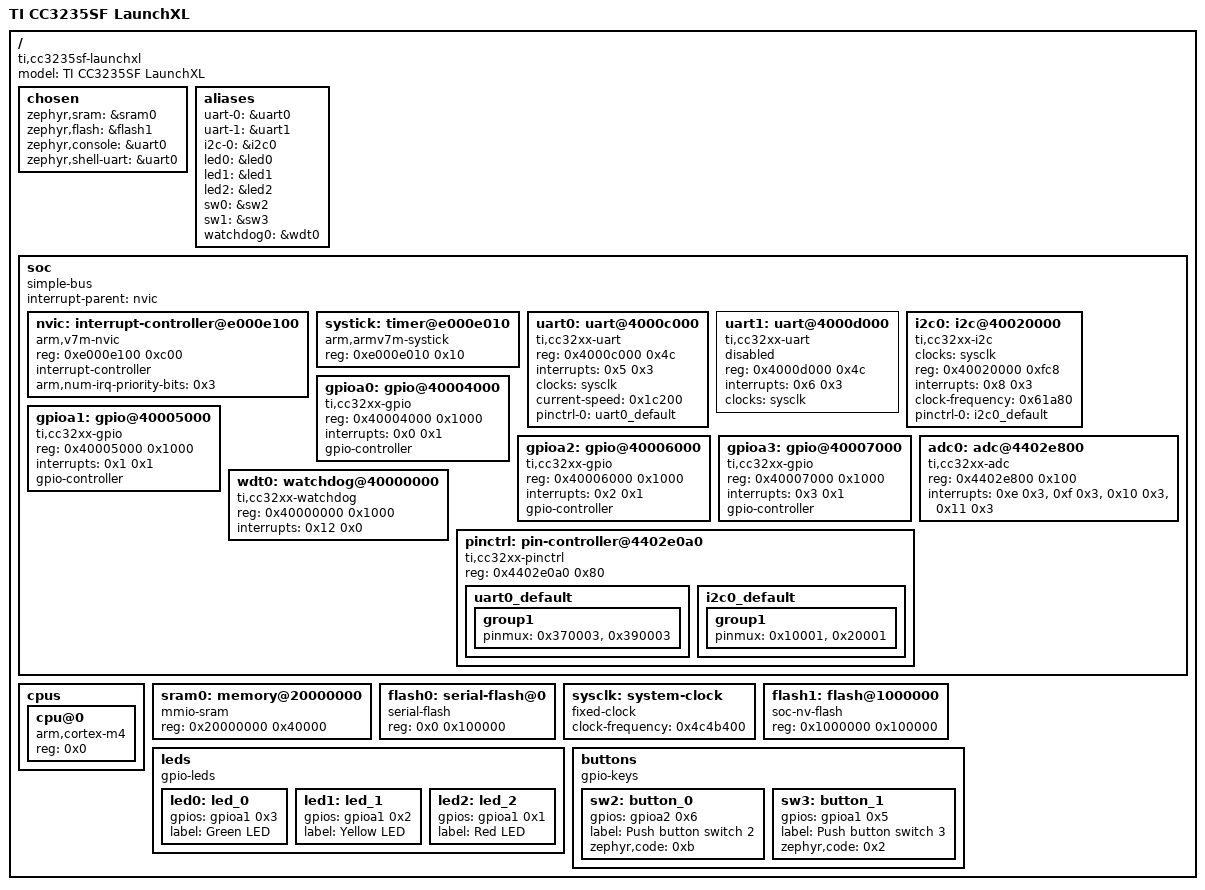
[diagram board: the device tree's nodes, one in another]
/dts-v1/;

/* node '/' defined in zephyr/dts/common/skeleton.dtsi:9 */
/ {
	#address-cells = < 0x1 >;            /* in zephyr/dts/common/skeleton.dtsi:10 */
	#size-cells = < 0x1 >;               /* in zephyr/dts/common/skeleton.dtsi:11 */
	model = "TI CC3235SF LaunchXL";      /* in zephyr/boards/ti/cc3235sf_launchxl/cc3235sf_launchxl.dts:14 */
	compatible = "ti,cc3235sf-launchxl",
	             "ti,cc3235sf",
	             "ti,cc32xx";            /* in zephyr/boards/ti/cc3235sf_launchxl/cc3235sf_launchxl.dts:15 */

	/* node '/chosen' defined in zephyr/dts/common/skeleton.dtsi:13 */
	chosen {
		zephyr,sram = &sram0;       /* in zephyr/boards/ti/cc3235sf_launchxl/cc3235sf_launchxl.dts:31 */
		zephyr,flash = &flash1;     /* in zephyr/boards/ti/cc3235sf_launchxl/cc3235sf_launchxl.dts:32 */
		zephyr,console = &uart0;    /* in zephyr/boards/ti/cc3235sf_launchxl/cc3235sf_launchxl.dts:33 */
		zephyr,shell-uart = &uart0; /* in zephyr/boards/ti/cc3235sf_launchxl/cc3235sf_launchxl.dts:34 */
	};

	/* node '/aliases' defined in zephyr/dts/common/skeleton.dtsi:15 */
	aliases {
		uart-0 = &uart0;   /* in zephyr/boards/ti/cc3235sf_launchxl/cc3235sf_launchxl.dts:18 */
		uart-1 = &uart1;   /* in zephyr/boards/ti/cc3235sf_launchxl/cc3235sf_launchxl.dts:19 */
		i2c-0 = &i2c0;     /* in zephyr/boards/ti/cc3235sf_launchxl/cc3235sf_launchxl.dts:20 */
		led0 = &led0;      /* in zephyr/boards/ti/cc3235sf_launchxl/cc3235sf_launchxl.dts:21 */
		led1 = &led1;      /* in zephyr/boards/ti/cc3235sf_launchxl/cc3235sf_launchxl.dts:22 */
		led2 = &led2;      /* in zephyr/boards/ti/cc3235sf_launchxl/cc3235sf_launchxl.dts:23 */
		sw0 = &sw2;        /* in zephyr/boards/ti/cc3235sf_launchxl/cc3235sf_launchxl.dts:25 */
		sw1 = &sw3;        /* in zephyr/boards/ti/cc3235sf_launchxl/cc3235sf_launchxl.dts:26 */
		watchdog0 = &wdt0; /* in zephyr/boards/ti/cc3235sf_launchxl/cc3235sf_launchxl.dts:27 */
	};

	/* node '/soc' defined in zephyr/dts/arm/armv7-m.dtsi:6 */
	soc {
		#address-cells = < 0x1 >;     /* in zephyr/dts/arm/armv7-m.dtsi:7 */
		#size-cells = < 0x1 >;        /* in zephyr/dts/arm/armv7-m.dtsi:8 */
		compatible = "simple-bus";    /* in zephyr/dts/arm/armv7-m.dtsi:9 */
		interrupt-parent = < &nvic >; /* in zephyr/dts/arm/armv7-m.dtsi:10 */
		ranges;                       /* in zephyr/dts/arm/armv7-m.dtsi:11 */

		/* node '/soc/interrupt-controller@e000e100' defined in zephyr/dts/arm/armv7-m.dtsi:13 */
		nvic: interrupt-controller@e000e100 {
			#address-cells = < 0x1 >;            /* in zephyr/dts/arm/armv7-m.dtsi:14 */
			compatible = "arm,v7m-nvic";         /* in zephyr/dts/arm/armv7-m.dtsi:15 */
			reg = < 0xe000e100 0xc00 >;          /* in zephyr/dts/arm/armv7-m.dtsi:16 */
			interrupt-controller;                /* in zephyr/dts/arm/armv7-m.dtsi:17 */
			#interrupt-cells = < 0x2 >;          /* in zephyr/dts/arm/armv7-m.dtsi:18 */
			arm,num-irq-priority-bits = < 0x3 >; /* in zephyr/dts/arm/ti/cc32xx.dtsi:142 */
			phandle = < 0x1 >;                   /* in zephyr/dts/arm/armv7-m.dtsi:10 */
		};

		/* node '/soc/timer@e000e010' defined in zephyr/dts/arm/armv7-m.dtsi:21 */
		systick: timer@e000e010 {
			compatible = "arm,armv7m-systick"; /* in zephyr/dts/arm/armv7-m.dtsi:22 */
			reg = < 0xe000e010 0x10 >;         /* in zephyr/dts/arm/armv7-m.dtsi:23 */
		};

		/* node '/soc/uart@4000c000' defined in zephyr/dts/arm/ti/cc32xx.dtsi:60 */
		uart0: uart@4000c000 {
			compatible = "ti,cc32xx-uart";  /* in zephyr/dts/arm/ti/cc32xx.dtsi:61 */
			reg = < 0x4000c000 0x4c >;      /* in zephyr/dts/arm/ti/cc32xx.dtsi:62 */
			interrupts = < 0x5 0x3 >;       /* in zephyr/dts/arm/ti/cc32xx.dtsi:63 */
			clocks = < &sysclk >;           /* in zephyr/dts/arm/ti/cc32xx.dtsi:64 */
			status = "okay";                /* in zephyr/boards/ti/cc3235sf_launchxl/cc3235sf_launchxl.dts:80 */
			current-speed = < 0x1c200 >;    /* in zephyr/boards/ti/cc3235sf_launchxl/cc3235sf_launchxl.dts:81 */
			pinctrl-0 = < &uart0_default >; /* in zephyr/boards/ti/cc3235sf_launchxl/cc3235sf_launchxl.dts:82 */
			pinctrl-names = "default";      /* in zephyr/boards/ti/cc3235sf_launchxl/cc3235sf_launchxl.dts:83 */
		};

		/* node '/soc/uart@4000d000' defined in zephyr/dts/arm/ti/cc32xx.dtsi:68 */
		uart1: uart@4000d000 {
			compatible = "ti,cc32xx-uart"; /* in zephyr/dts/arm/ti/cc32xx.dtsi:69 */
			reg = < 0x4000d000 0x4c >;     /* in zephyr/dts/arm/ti/cc32xx.dtsi:70 */
			interrupts = < 0x6 0x3 >;      /* in zephyr/dts/arm/ti/cc32xx.dtsi:71 */
			clocks = < &sysclk >;          /* in zephyr/dts/arm/ti/cc32xx.dtsi:72 */
			status = "disabled";           /* in zephyr/dts/arm/ti/cc32xx.dtsi:73 */
		};

		/* node '/soc/i2c@40020000' defined in zephyr/dts/arm/ti/cc32xx.dtsi:76 */
		i2c0: i2c@40020000 {
			compatible = "ti,cc32xx-i2c";  /* in zephyr/dts/arm/ti/cc32xx.dtsi:77 */
			clocks = < &sysclk >;          /* in zephyr/dts/arm/ti/cc32xx.dtsi:78 */
			#address-cells = < 0x1 >;      /* in zephyr/dts/arm/ti/cc32xx.dtsi:80 */
			#size-cells = < 0x0 >;         /* in zephyr/dts/arm/ti/cc32xx.dtsi:81 */
			reg = < 0x40020000 0xfc8 >;    /* in zephyr/dts/arm/ti/cc32xx.dtsi:82 */
			interrupts = < 0x8 0x3 >;      /* in zephyr/dts/arm/ti/cc32xx.dtsi:83 */
			status = "okay";               /* in zephyr/boards/ti/cc3235sf_launchxl/cc3235sf_launchxl.dts:87 */
			clock-frequency = < 0x61a80 >; /* in zephyr/boards/ti/cc3235sf_launchxl/cc3235sf_launchxl.dts:88 */
			pinctrl-0 = < &i2c0_default >; /* in zephyr/boards/ti/cc3235sf_launchxl/cc3235sf_launchxl.dts:89 */
			pinctrl-names = "default";     /* in zephyr/boards/ti/cc3235sf_launchxl/cc3235sf_launchxl.dts:90 */
		};

		/* node '/soc/gpio@40004000' defined in zephyr/dts/arm/ti/cc32xx.dtsi:87 */
		gpioa0: gpio@40004000 {
			compatible = "ti,cc32xx-gpio"; /* in zephyr/dts/arm/ti/cc32xx.dtsi:88 */
			reg = < 0x40004000 0x1000 >;   /* in zephyr/dts/arm/ti/cc32xx.dtsi:89 */
			interrupts = < 0x0 0x1 >;      /* in zephyr/dts/arm/ti/cc32xx.dtsi:90 */
			gpio-controller;               /* in zephyr/dts/arm/ti/cc32xx.dtsi:91 */
			#gpio-cells = < 0x2 >;         /* in zephyr/dts/arm/ti/cc32xx.dtsi:92 */
		};

		/* node '/soc/gpio@40005000' defined in zephyr/dts/arm/ti/cc32xx.dtsi:95 */
		gpioa1: gpio@40005000 {
			compatible = "ti,cc32xx-gpio"; /* in zephyr/dts/arm/ti/cc32xx.dtsi:96 */
			reg = < 0x40005000 0x1000 >;   /* in zephyr/dts/arm/ti/cc32xx.dtsi:97 */
			interrupts = < 0x1 0x1 >;      /* in zephyr/dts/arm/ti/cc32xx.dtsi:98 */
			gpio-controller;               /* in zephyr/dts/arm/ti/cc32xx.dtsi:99 */
			#gpio-cells = < 0x2 >;         /* in zephyr/dts/arm/ti/cc32xx.dtsi:100 */
			phandle = < 0x5 >;             /* in zephyr/boards/ti/cc3235sf_launchxl/cc3235sf_launchxl.dts:41 */
		};

		/* node '/soc/gpio@40006000' defined in zephyr/dts/arm/ti/cc32xx.dtsi:103 */
		gpioa2: gpio@40006000 {
			compatible = "ti,cc32xx-gpio"; /* in zephyr/dts/arm/ti/cc32xx.dtsi:104 */
			reg = < 0x40006000 0x1000 >;   /* in zephyr/dts/arm/ti/cc32xx.dtsi:105 */
			interrupts = < 0x2 0x1 >;      /* in zephyr/dts/arm/ti/cc32xx.dtsi:106 */
			gpio-controller;               /* in zephyr/dts/arm/ti/cc32xx.dtsi:107 */
			#gpio-cells = < 0x2 >;         /* in zephyr/dts/arm/ti/cc32xx.dtsi:108 */
			phandle = < 0x6 >;             /* in zephyr/boards/ti/cc3235sf_launchxl/cc3235sf_launchxl.dts:61 */
		};

		/* node '/soc/gpio@40007000' defined in zephyr/dts/arm/ti/cc32xx.dtsi:111 */
		gpioa3: gpio@40007000 {
			compatible = "ti,cc32xx-gpio"; /* in zephyr/dts/arm/ti/cc32xx.dtsi:112 */
			reg = < 0x40007000 0x1000 >;   /* in zephyr/dts/arm/ti/cc32xx.dtsi:113 */
			interrupts = < 0x3 0x1 >;      /* in zephyr/dts/arm/ti/cc32xx.dtsi:114 */
			gpio-controller;               /* in zephyr/dts/arm/ti/cc32xx.dtsi:115 */
			#gpio-cells = < 0x2 >;         /* in zephyr/dts/arm/ti/cc32xx.dtsi:116 */
		};

		/* node '/soc/adc@4402e800' defined in zephyr/dts/arm/ti/cc32xx.dtsi:119 */
		adc0: adc@4402e800 {
			compatible = "ti,cc32xx-adc"; /* in zephyr/dts/arm/ti/cc32xx.dtsi:120 */
			reg = < 0x4402e800 0x100 >;   /* in zephyr/dts/arm/ti/cc32xx.dtsi:121 */
			interrupts = < 0xe 0x3 >,
			             < 0xf 0x3 >,
			             < 0x10 0x3 >,
			             < 0x11 0x3 >;    /* in zephyr/dts/arm/ti/cc32xx.dtsi:122 */
			#io-channel-cells = < 0x1 >;  /* in zephyr/dts/arm/ti/cc32xx.dtsi:124 */
			status = "okay";              /* in zephyr/boards/ti/cc3235sf_launchxl/cc3235sf_launchxl.dts:76 */
		};

		/* node '/soc/watchdog@40000000' defined in zephyr/dts/arm/ti/cc32xx.dtsi:127 */
		wdt0: watchdog@40000000 {
			compatible = "ti,cc32xx-watchdog"; /* in zephyr/dts/arm/ti/cc32xx.dtsi:128 */
			reg = < 0x40000000 0x1000 >;       /* in zephyr/dts/arm/ti/cc32xx.dtsi:129 */
			interrupts = < 0x12 0x0 >;         /* in zephyr/dts/arm/ti/cc32xx.dtsi:130 */
			status = "okay";                   /* in zephyr/boards/ti/cc3235sf_launchxl/cc3235sf_launchxl.dts:94 */
		};

		/* node '/soc/pin-controller@4402e0a0' defined in zephyr/dts/arm/ti/cc32xx.dtsi:134 */
		pinctrl: pin-controller@4402e0a0 {
			compatible = "ti,cc32xx-pinctrl"; /* in zephyr/dts/arm/ti/cc32xx.dtsi:135 */
			reg = < 0x4402e0a0 0x80 >;        /* in zephyr/dts/arm/ti/cc32xx.dtsi:136 */

			/* node '/soc/pin-controller@4402e0a0/uart0_default' defined in zephyr/boards/ti/cc3235sf_launchxl/cc3235sf_launchxl-pinctrl.dtsi:9 */
			uart0_default: uart0_default {
				phandle = < 0x3 >; /* in zephyr/boards/ti/cc3235sf_launchxl/cc3235sf_launchxl.dts:82 */

				/* node '/soc/pin-controller@4402e0a0/uart0_default/group1' defined in zephyr/boards/ti/cc3235sf_launchxl/cc3235sf_launchxl-pinctrl.dtsi:10 */
				group1 {
					pinmux = < 0x370003 >,
					         < 0x390003 >; /* in zephyr/boards/ti/cc3235sf_launchxl/cc3235sf_launchxl-pinctrl.dtsi:11 */
				};
			};

			/* node '/soc/pin-controller@4402e0a0/i2c0_default' defined in zephyr/boards/ti/cc3235sf_launchxl/cc3235sf_launchxl-pinctrl.dtsi:15 */
			i2c0_default: i2c0_default {
				phandle = < 0x4 >; /* in zephyr/boards/ti/cc3235sf_launchxl/cc3235sf_launchxl.dts:89 */

				/* node '/soc/pin-controller@4402e0a0/i2c0_default/group1' defined in zephyr/boards/ti/cc3235sf_launchxl/cc3235sf_launchxl-pinctrl.dtsi:16 */
				group1 {
					pinmux = < 0x10001 >,
					         < 0x20001 >; /* in zephyr/boards/ti/cc3235sf_launchxl/cc3235sf_launchxl-pinctrl.dtsi:17 */
				};
			};
		};
	};

	/* node '/cpus' defined in zephyr/dts/arm/ti/cc32xx.dtsi:34 */
	cpus {
		#address-cells = < 0x1 >; /* in zephyr/dts/arm/ti/cc32xx.dtsi:35 */
		#size-cells = < 0x0 >;    /* in zephyr/dts/arm/ti/cc32xx.dtsi:36 */

		/* node '/cpus/cpu@0' defined in zephyr/dts/arm/ti/cc32xx.dtsi:38 */
		cpu@0 {
			device_type = "cpu";          /* in zephyr/dts/arm/ti/cc32xx.dtsi:39 */
			compatible = "arm,cortex-m4"; /* in zephyr/dts/arm/ti/cc32xx.dtsi:40 */
			reg = < 0x0 >;                /* in zephyr/dts/arm/ti/cc32xx.dtsi:41 */
		};
	};

	/* node '/memory@20000000' defined in zephyr/dts/arm/ti/cc32xx.dtsi:45 */
	sram0: memory@20000000 {
		compatible = "mmio-sram";     /* in zephyr/dts/arm/ti/cc32xx.dtsi:46 */
		reg = < 0x20000000 0x40000 >; /* in zephyr/dts/arm/ti/cc3235sf.dtsi:12 */
	};

	/* node '/serial-flash@0' defined in zephyr/dts/arm/ti/cc32xx.dtsi:49 */
	flash0: serial-flash@0 {
		compatible = "serial-flash"; /* in zephyr/dts/arm/ti/cc32xx.dtsi:50 */
		reg = < 0x0 0x100000 >;      /* in zephyr/dts/arm/ti/cc3235sf.dtsi:16 */
	};

	/* node '/system-clock' defined in zephyr/dts/arm/ti/cc32xx.dtsi:53 */
	sysclk: system-clock {
		compatible = "fixed-clock";      /* in zephyr/dts/arm/ti/cc32xx.dtsi:54 */
		clock-frequency = < 0x4c4b400 >; /* in zephyr/dts/arm/ti/cc32xx.dtsi:55 */
		#clock-cells = < 0x0 >;          /* in zephyr/dts/arm/ti/cc32xx.dtsi:56 */
		phandle = < 0x2 >;               /* in zephyr/dts/arm/ti/cc32xx.dtsi:64 */
	};

	/* node '/flash@1000000' defined in zephyr/dts/arm/ti/cc3235sf.dtsi:19 */
	flash1: flash@1000000 {
		compatible = "soc-nv-flash";  /* in zephyr/dts/arm/ti/cc3235sf.dtsi:20 */
		reg = < 0x1000000 0x100000 >; /* in zephyr/dts/arm/ti/cc3235sf.dtsi:21 */
	};

	/* node '/leds' defined in zephyr/boards/ti/cc3235sf_launchxl/cc3235sf_launchxl.dts:37 */
	leds {
		compatible = "gpio-leds"; /* in zephyr/boards/ti/cc3235sf_launchxl/cc3235sf_launchxl.dts:38 */

		/* node '/leds/led_0' defined in zephyr/boards/ti/cc3235sf_launchxl/cc3235sf_launchxl.dts:40 */
		led0: led_0 {
			gpios = < &gpioa1 0x3 0x0 >; /* in zephyr/boards/ti/cc3235sf_launchxl/cc3235sf_launchxl.dts:41 */
			label = "Green LED";         /* in zephyr/boards/ti/cc3235sf_launchxl/cc3235sf_launchxl.dts:42 */
		};

		/* node '/leds/led_1' defined in zephyr/boards/ti/cc3235sf_launchxl/cc3235sf_launchxl.dts:45 */
		led1: led_1 {
			gpios = < &gpioa1 0x2 0x0 >; /* in zephyr/boards/ti/cc3235sf_launchxl/cc3235sf_launchxl.dts:46 */
			label = "Yellow LED";        /* in zephyr/boards/ti/cc3235sf_launchxl/cc3235sf_launchxl.dts:47 */
		};

		/* node '/leds/led_2' defined in zephyr/boards/ti/cc3235sf_launchxl/cc3235sf_launchxl.dts:50 */
		led2: led_2 {
			gpios = < &gpioa1 0x1 0x0 >; /* in zephyr/boards/ti/cc3235sf_launchxl/cc3235sf_launchxl.dts:51 */
			label = "Red LED";           /* in zephyr/boards/ti/cc3235sf_launchxl/cc3235sf_launchxl.dts:52 */
		};
	};

	/* node '/buttons' defined in zephyr/boards/ti/cc3235sf_launchxl/cc3235sf_launchxl.dts:56 */
	buttons {
		compatible = "gpio-keys"; /* in zephyr/boards/ti/cc3235sf_launchxl/cc3235sf_launchxl.dts:58 */

		/* node '/buttons/button_0' defined in zephyr/boards/ti/cc3235sf_launchxl/cc3235sf_launchxl.dts:60 */
		sw2: button_0 {
			gpios = < &gpioa2 0x6 0x0 >;    /* in zephyr/boards/ti/cc3235sf_launchxl/cc3235sf_launchxl.dts:61 */
			label = "Push button switch 2"; /* in zephyr/boards/ti/cc3235sf_launchxl/cc3235sf_launchxl.dts:62 */
			zephyr,code = < 0xb >;          /* in zephyr/boards/ti/cc3235sf_launchxl/cc3235sf_launchxl.dts:63 */
		};

		/* node '/buttons/button_1' defined in zephyr/boards/ti/cc3235sf_launchxl/cc3235sf_launchxl.dts:67 */
		sw3: button_1 {
			gpios = < &gpioa1 0x5 0x0 >;    /* in zephyr/boards/ti/cc3235sf_launchxl/cc3235sf_launchxl.dts:68 */
			label = "Push button switch 3"; /* in zephyr/boards/ti/cc3235sf_launchxl/cc3235sf_launchxl.dts:69 */
			zephyr,code = < 0x2 >;          /* in zephyr/boards/ti/cc3235sf_launchxl/cc3235sf_launchxl.dts:70 */
		};
	};
};
